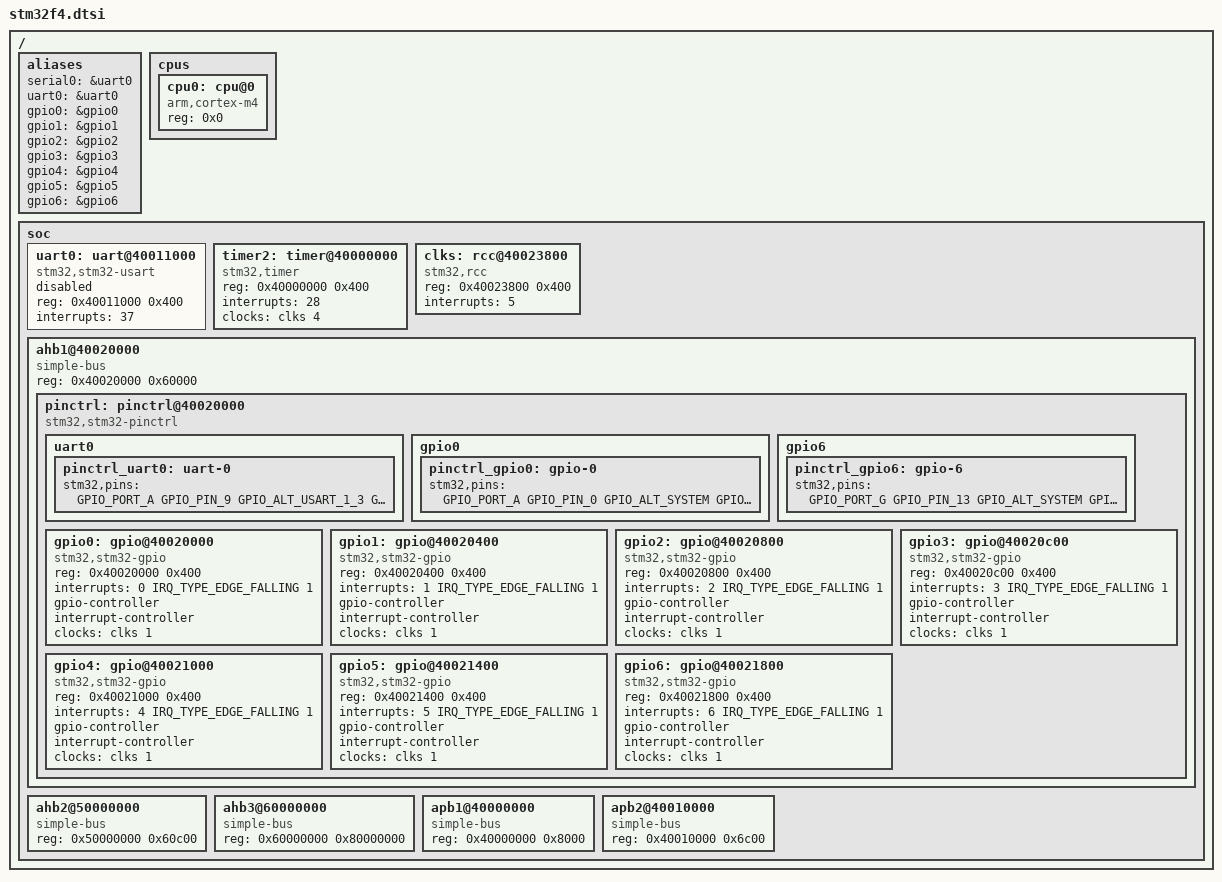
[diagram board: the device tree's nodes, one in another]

#include <dt-bindings/interrupt-controller/irq.h>
#include <dt-bindings/gpio/gpio.h>
#include "armv7-m.dtsi"
#include "stm32-pinfunc.h"

/ {
	aliases {
		serial0 = &uart0;
		uart0 = &uart0;
		gpio0 = &gpio0;
		gpio1 = &gpio1;
		gpio2 = &gpio2;
		gpio3 = &gpio3;
		gpio4 = &gpio4;
		gpio5 = &gpio5;
		gpio6 = &gpio6;

	};

	cpus {
		#size-cells = <0>;
		#address-cells = <1>;

		cpu0: cpu@0 {
			device_type = "cpu";
			compatible = "arm,cortex-m4";
			reg = <0x0>;
		};
	};

	soc {

		
		uart0: uart@40011000 { /* USART0 */
			compatible = "stm32,stm32-usart";
			reg = <0x40011000 0x400>;
			interrupts = <37>;
			status = "disabled";
			/*
			pinctrl-names = "default";
			pinctrl-0 = <&pinctrl_uart0>;
			*/
		};
		
		timer2: timer@40000000 {
			compatible = "stm32,timer";
			reg = <0x40000000 0x400>;
			interrupts = <28>;
			#clock-cells = <1>;
			clocks = <&clks 4>;
		};
		
		clks: rcc@40023800 {
			compatible = "stm32,rcc";
			reg = <0x40023800 0x400>;
			interrupts = <5>;
			#clock-cells = <1>;
		};
		
		ahb1@40020000 { /* AHB1 bus 168MHz */
			compatible = "simple-bus";
			reg = <0x40020000 0x60000>;
			#address-cells = <1>;
			#size-cells = <1>;
			ranges;

			/* peryferia */
			pinctrl: pinctrl@40020000 { /* GPIOA-K */
				#address-cells = <1>;
				#size-cells = <1>;
				compatible = "stm32,stm32-pinctrl", "simple-bus";
				ranges = <0x40020000 0x40020000 0x2C00>; /* 0x400*0xB */
				
				uart0 {
					pinctrl_uart0: uart-0 {
						stm32,pins =
							<GPIO_PORT_A GPIO_PIN_9 GPIO_ALT_USART_1_3 GPIO_PIN_CONFIG(0,GPIO_MODER_IN, GPIO_OTYPER_PP, GPIO_OSPEEDR_FS, GPIO_PUPDR_PUP)
							 GPIO_PORT_A GPIO_PIN_10 GPIO_ALT_USART_1_3 GPIO_PIN_CONFIG(0,GPIO_MODER_OUT, GPIO_OTYPER_OD, GPIO_OSPEEDR_FS, GPIO_PUPDR_PDOWN) >;
					};
				};
				
				gpio0 {
					pinctrl_gpio0: gpio-0 {
						stm32,pins =
							<GPIO_PORT_A GPIO_PIN_0 GPIO_ALT_SYSTEM GPIO_PIN_CONFIG(1, GPIO_MODER_IN, GPIO_OTYPER_PP, GPIO_OSPEEDR_LS, GPIO_PUPDR_PUP)
							 GPIO_PORT_A GPIO_PIN_9 GPIO_ALT_SYSTEM GPIO_PIN_CONFIG(1, GPIO_MODER_IN, GPIO_OTYPER_PP, GPIO_OSPEEDR_FS, GPIO_PUPDR_PUP)
							 GPIO_PORT_A GPIO_PIN_10 GPIO_ALT_SYSTEM GPIO_PIN_CONFIG(1, GPIO_MODER_OUT, GPIO_OTYPER_OD, GPIO_OSPEEDR_FS, GPIO_PUPDR_PDOWN) >;
					};
				};
				
				gpio6 {
					pinctrl_gpio6: gpio-6 {
						stm32,pins =
							<GPIO_PORT_G GPIO_PIN_13 GPIO_ALT_SYSTEM GPIO_PIN_CONFIG(0, GPIO_MODER_OUT, GPIO_OTYPER_PP, GPIO_OSPEEDR_LS, GPIO_PUPDR_PDOWN)
							 GPIO_PORT_G GPIO_PIN_14 GPIO_ALT_SYSTEM GPIO_PIN_CONFIG(0, GPIO_MODER_OUT, GPIO_OTYPER_PP, GPIO_OSPEEDR_LS, GPIO_PUPDR_PDOWN) >;
					};
				};
					
					
				gpio0: gpio@40020000 {
					compatible = "stm32,stm32-gpio";
					reg = <0x40020000 0x400>;
					interrupts = <0 IRQ_TYPE_EDGE_FALLING 1>;
					#gpio-cells = <2>;
					gpio-controller;
					interrupt-controller;
					#interrupt-cells = <2>;
					clocks = <&clks 1>;
					/*
					pinctrl-names = "default";
					pinctrl-0 = <&pinctrl_gpio0>;
					*/
				};
				
				gpio1: gpio@40020400 {
					compatible = "stm32,stm32-gpio";
					reg = <0x40020400 0x400>;
					interrupts = <1 IRQ_TYPE_EDGE_FALLING 1>;
					#gpio-cells = <2>;
					gpio-controller;
					interrupt-controller;
					#interrupt-cells = <2>;
					clocks = <&clks 1>;
				};
				
				gpio2: gpio@40020800 {
					compatible = "stm32,stm32-gpio";
					reg = <0x40020800 0x400>;
					interrupts = <2 IRQ_TYPE_EDGE_FALLING 1>;
					#gpio-cells = <2>;
					gpio-controller;
					interrupt-controller;
					#interrupt-cells = <2>;
					clocks = <&clks 1>;
				};
				
				gpio3: gpio@40020c00 {
					compatible = "stm32,stm32-gpio";
					reg = <0x40020c00 0x400>;
					interrupts = <3 IRQ_TYPE_EDGE_FALLING 1>;
					#gpio-cells = <2>;
					gpio-controller;
					interrupt-controller;
					#interrupt-cells = <2>;
					clocks = <&clks 1>;
				};
				
				gpio4: gpio@40021000 {
					compatible = "stm32,stm32-gpio";
					reg = <0x40021000 0x400>;
					interrupts = <4 IRQ_TYPE_EDGE_FALLING 1>;
					#gpio-cells = <2>;
					gpio-controller;
					interrupt-controller;
					#interrupt-cells = <2>;
					clocks = <&clks 1>;
				};
				
				gpio5: gpio@40021400 {
					compatible = "stm32,stm32-gpio";
					reg = <0x40021400 0x400>;
					interrupts = <5 IRQ_TYPE_EDGE_FALLING 1>;
					#gpio-cells = <2>;
					gpio-controller;
					interrupt-controller;
					#interrupt-cells = <2>;
					clocks = <&clks 1>;
				};
								
				gpio6: gpio@40021800 {
					compatible = "stm32,stm32-gpio";
					reg = <0x40021800 0x400>;
					interrupts = <6 IRQ_TYPE_EDGE_FALLING 1>;
					#gpio-cells = <2>;
					gpio-controller;
					interrupt-controller;
					#interrupt-cells = <2>;
					clocks = <&clks 1>;
				};
				
			};
		};
		
		ahb2@50000000 { /* AHB2 bus 168MHz */
			compatible = "simple-bus";
			reg = <0x50000000 0x60c00>;
			#address-cells = <1>;
			#size-cells = <1>;
			ranges;
			
			/* peryferia */
		
		};
		
		ahb3@60000000 { /* AHB3 bus 168MHz */
			compatible = "simple-bus";
			reg = <0x60000000 0x80000000>;
			#address-cells = <1>;
			#size-cells = <1>;
			ranges;
			
			/* peryferia */
		
		};

		apb1@40000000 { /* APB1 bus 42MHz */
			compatible = "simple-bus";
			reg = <0x40000000 0x8000>;
			#address-cells = <1>;
			#size-cells = <1>;
			ranges;
			
			/* peryferia */
		
		};
		
		apb2@40010000 { /* APB2 bus 84MHz */
			compatible = "simple-bus";
			reg = <0x40010000 0x6c00>;
			#address-cells = <1>;
			#size-cells = <1>;
			ranges;
			
			/* peryferia */
		
		};
	};
};
